AUTOSAR XML (schema 00047)
package /DemoApplication/ImplementationDataTypes
  impl type E2EProt_Data: category=STRUCTURE
    element SafetyE2E_Data: implementation-data-type=uint8
    element SafetyE2E_Data_CRC: implementation-data-type=uint16
    element SafetyE2E_Data_SQC_Counter: implementation-data-type=uint8
package /DemoApplication/PortInterfaces
  sender receiver interface E2EProt_Data
    data E2EProt_Data: sw-impl-policy=QUEUED, type=E2EProt_Data
package /DemoApplication/SwcImplementations
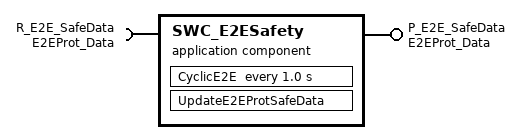
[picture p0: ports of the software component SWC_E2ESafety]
  application sw component type SWC_E2ESafety
    provide port P_E2E_SafeData: provided-interface=E2EProt_Data
    require port R_E2E_SafeData: required-interface=E2EProt_Data
    behavior IB_SWC_E2ESafety: handle-termination-and-restart=NO-SUPPORT
      data received event SafeE2EProtDataReceived: start-on-event=UpdateE2EProtSafeData, data=R_E2E_SafeData.E2EProt_Data
      timing event CyclicEventE2E: start-on-event=CyclicE2E, period=1.0
      runnable UpdateE2EProtSafeData: symbol=SWC_E2EProtSafe_Data_Received
        data-receive-point-by-arguments:
          access E2ESafeDataIn: accessed-variable=R_E2E_SafeData.E2EProt_Data
        data-write-access:
          access E2ESafeDataOut: accessed-variable=P_E2E_SafeData.E2EProt_Data
      runnable CyclicE2E: symbol=SWC_E2EProtSafe_Data_Cyclic
        data-send-points:
          access E2ESafeDataOut: accessed-variable=P_E2E_SafeData.E2EProt_Data
  swc implementation Impl_SWC_E2EProtSafety: programming-language=C, sw-version=1.0.0, vendor-id=1, behavior=IB_SWC_E2ESafety
    code-descriptors:
      code SRC: artifact-descriptors=autosar-engineering-object={short-label=EngObject, category=SWSRC}
    resource consumption Resources
      memory section RTE_START_SEC_APPL_CODE: sw-addrmethod=CODE, symbol=CODE
